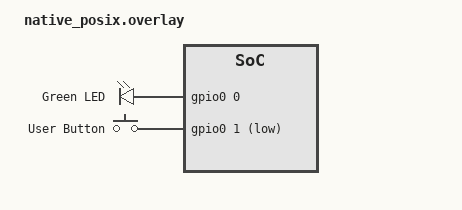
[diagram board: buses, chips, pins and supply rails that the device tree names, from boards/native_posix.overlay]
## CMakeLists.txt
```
# SPDX-License-Identifier: Apache-2.0

cmake_minimum_required(VERSION 3.20.0)

# 1. Tell Zephyr where your out-of-tree module is
set(ZEPHYR_EXTRA_MODULES /home/victor/Documents/Mestrado-UFAL-PPGI/BTreeFy/btreefy-repo)
find_package(Zephyr REQUIRED HINTS $ENV{ZEPHYR_BASE})
project(app LANGUAGES C)

target_sources(app
               PRIVATE
               src/main.c
               src/door_operator_controller.c
               src/btf_nodes_generated.c)

target_link_libraries(app PUBLIC BTreeFy-Src)
```

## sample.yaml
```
sample:
  name: BTreeFy Door Controller
tests:
  example.btreefy.door_controller:
    tags:
      - btreefy
      - behavior-tree
      - gpio
    filter: dt_enabled_alias_with_parent_compat("led0", "gpio-leds") and dt_node_has_alias("sw0")
    depends_on: gpio
    harness: console
    integration_platforms:
      - native_posix
```

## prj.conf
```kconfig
CONFIG_GPIO=y
CONFIG_EVENTS=y
# First config to get POSIX thread running w/o statically allocated stack
CONFIG_POSIX_API=y
CONFIG_THREAD_STACK_INFO=y
CONFIG_DYNAMIC_THREAD=y
CONFIG_DYNAMIC_THREAD_POOL_SIZE=6
CONFIG_MAX_PTHREAD_MUTEX_COUNT=6

# BTreeFy Runner Selection
# CONFIG_BTREEFY_RUNNER_ZEPHYR=y
# Default is POSIX if not set
```

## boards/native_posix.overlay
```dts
/ {
        aliases {
                led0 = &led0;
                sw0 = &button0;
        };

        leds {
                compatible = "gpio-leds";
                led0: led_0 {
                        gpios = <&gpio0 0 GPIO_ACTIVE_HIGH>;
                        label = "Green LED";
                };
        };

        buttons {
                compatible = "gpio-keys";
                button0: button_0 {
                        gpios = <&gpio0 1 (GPIO_PULL_UP | GPIO_ACTIVE_LOW)>;
                        label = "User Button";
                };
        };
};

&gpio0 {
        status = "okay";
        ngpios = <32>;
};
```

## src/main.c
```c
/*
 * Copyright (c) 2016 Intel Corporation
 *
 * SPDX-License-Identifier: Apache-2.0
 */

#include <stdbool.h>
#include <stdio.h>
#include <zephyr/drivers/gpio.h>
#include <zephyr/kernel.h>

#include "app_blackboard.h"
#include "btreefy/btf_blackboard.h"
#include "btreefy/btf_tree_runner.h"
#include "btreefy/btreefy.h"
#include "door_operator_controller.h"

/* 1000 msec = 1 sec */
#define SLEEP_TIME_MS 1000

/* The devicetree node identifier for the "led0" alias. */
#define LED0_NODE DT_ALIAS(led0)

/*
 * Get button configuration from the devicetree sw0 alias. This is mandatory.
 */
#define SW0_NODE DT_ALIAS(sw0)
#if !DT_NODE_HAS_STATUS(SW0_NODE, okay)
#error "Unsupported board: sw0 devicetree alias is not defined"
#endif

extern struct btf_node nodes[];
extern size_t          nodes_size;

/*
 * A build error on this line means your board is unsupported.
 * See the sample documentation for information on how to fix this.
 */
static const struct gpio_dt_spec led = GPIO_DT_SPEC_GET(LED0_NODE, gpios);

static const struct gpio_dt_spec button =
    GPIO_DT_SPEC_GET_OR(SW0_NODE, gpios, {0});
static struct gpio_callback button_cb_data;

static enum btf_node_status mock_open_door_action_status  = BTF_SUCCESS_STATUS;
static enum btf_node_status mock_close_door_action_status = BTF_SUCCESS_STATUS;
static enum btf_node_status mock_stop_door_action_status  = BTF_SUCCESS_STATUS;

static uint8_t button_pressed_count = 0;

static struct k_timer button_timer;
static void           button_timer_cb(struct k_timer *timer_id);

BTF_BLACKBOARD_DEFINE(
    app_blackboard, struct app_blackboard,
    BTF_BLACKBOARD_INIT_VAL(.button_emergency = false, .open_request = false,
                            .close_request          = false,
                            .has_emergency_occurred = false,
                            .door_status            = BTFDT_DOOR_IS_OPEN,
                            .motor_status           = BTFDT_MOTOR_STOP_DOOR));

void button_pressed(const struct device *dev, struct gpio_callback *cb,
                    uint32_t pins)
{
    static int64_t last_button_pressed_evt_time = 0;

    int64_t current_time = k_uptime_get();

    if (current_time - last_button_pressed_evt_time > 50)
    {
        last_button_pressed_evt_time = current_time;
        if (button_pressed_count == 0)
        {
            k_timer_start(&button_timer, K_MSEC(800), K_NO_WAIT);
        }
        button_pressed_count++;
    }
}

void button_timer_cb(struct k_timer *timer_id)
{
    bool is_valid      = true;
    bool flag_occurred = true;

    printf("Button timer callback executed\nbutton_pressed_count = %d\n",
           button_pressed_count);

    switch (button_pressed_count)
    {
    case 1:
    {
        BTF_BLACKBOARD_UPDATE_DATA(app_blackboard, button_emergency,
                                   flag_occurred);
    }
    break;

    case 2:
    {
        BTF_BLACKBOARD_UPDATE_DATA(app_blackboard, open_request, flag_occurred);
        printf("Open request on timer callback\n");
    }
    break;

    case 3:
    {
        BTF_BLACKBOARD_UPDATE_DATA(app_blackboard, close_request,
                                   flag_occurred);
        printf("Close request on timer callback\n");
    }
    break;

    default:
        // Default
        break;
    }

    button_pressed_count = 0;
}

// ### BT ACTIONS - START ###

enum btf_node_status stop_door_action(struct btf_tree *tree, void *data,
                                   size_t datalen)
{
    printf("Door has stopped.\n");
    door_operator_ctrl_set_action(STOP_DOOR);

    return BTF_SUCCESS_STATUS;
}

enum btf_node_status open_door_action(struct btf_tree *tree, void *data,
                                   size_t datalen)
{
    enum btfdt_door_sensor_status door_status;

    printf("Door is opening... ");

    BTF_BLACKBOARD_RETRIEVE_DATA(app_blackboard, door_status, door_status);

    if (door_status != BTFDT_DOOR_IS_OPEN)
    {
        printf(" request ACCEPTED!\n");
        door_operator_ctrl_set_action(OPEN_DOOR);
    }
    else
    {
        printf(" but is alreaedy OPEN, then REJECTED!\n");
    }

    return BTF_SUCCESS_STATUS;
}

enum btf_node_status close_door_action(struct btf_tree *tree, void *data,
                                    size_t datalen)
{
    printf("Door is closing... ");
    door_operator_ctrl_set_action(CLOSE_DOOR);
    return mock_close_door_action_status;
}

enum btf_node_status emergency_action(struct btf_tree *tree, void *data,
                                   size_t datalen)
{
    bool flag_occurred = true;
    printf("Emergency occurred!\n");

    BTF_BLACKBOARD_UPDATE_DATA(app_blackboard, has_emergency_occurred,
                               flag_occurred);

    return BTF_SUCCESS_STATUS;
}

// ### BT ACTIONS - END ###

// ### BT CONDITIONS - START ###

enum btf_node_status is_motor_on_cond(struct btf_tree *tree, void *data,
                                   size_t datalen)
{
    enum btfdt_motor_action_status motor_status;

    BTF_BLACKBOARD_RETRIEVE_DATA(app_blackboard, motor_status, motor_status);

    return (motor_status == BTFDT_MOTOR_STOP_DOOR) ? BTF_FAILURE_STATUS
                                                   : BTF_SUCCESS_STATUS;
}

enum btf_node_status is_emerg_btn_pressed_cond(struct btf_tree *tree, void *data,
                                            size_t datalen)
{
    enum btf_node_status ret = BTF_FAILURE_STATUS;
    bool              flag_occurred;

    BTF_BLACKBOARD_RETRIEVE_DATA(app_blackboard, button_emergency,
                                 flag_occurred);

    if (flag_occurred)
    {
        printf("Emergency button pressed!\n");
        flag_occurred = false;
        BTF_BLACKBOARD_UPDATE_DATA(app_blackboard, button_emergency,
                                   flag_occurred);
        ret = BTF_SUCCESS_STATUS;
    }
    return ret;
}

enum btf_node_status is_open_cond(struct btf_tree *tree, void *data, size_t datalen)
{
    enum btf_node_status             ret = BTF_FAILURE_STATUS;
    enum btfdt_door_sensor_status door_status;

    BTF_BLACKBOARD_RETRIEVE_DATA(app_blackboard, door_status, door_status);

    if (door_status == BTFDT_DOOR_IS_OPEN)
    {
        ret = BTF_SUCCESS_STATUS;
        printf("Door is open\n");
    }
    else if (door_status == BTFDT_DOOR_IS_CLOSED)
    {
        printf("Door is closed\n");
    }

    return ret;
}

enum btf_node_status is_opening_cond(struct btf_tree *tree, void *data, size_t datalen)
{
    enum btf_node_status              ret = BTF_FAILURE_STATUS;
    enum btfdt_door_sensor_status  door_status;
    enum btfdt_motor_action_status motor_status;

    BTF_BLACKBOARD_RETRIEVE_DATA(app_blackboard, door_status, door_status);
    BTF_BLACKBOARD_RETRIEVE_DATA(app_blackboard, motor_status, motor_status);

    if ((door_status == BTFDT_DOOR_IS_UNDEFINED)
        && (motor_status == BTFDT_MOTOR_OPEN_DOOR))
    {
        ret = BTF_SUCCESS_STATUS;
    }

    return ret;
}

enum btf_node_status is_closed_cond(struct btf_tree *tree, void *data, size_t datalen)
{
    enum btf_node_status             ret = BTF_FAILURE_STATUS;
    enum btfdt_door_sensor_status door_status;

    BTF_BLACKBOARD_RETRIEVE_DATA(app_blackboard, door_status, door_status);

    if (door_status == BTFDT_DOOR_IS_CLOSED)
    {
        ret = BTF_SUCCESS_STATUS;
        printf("Door is closed\n");
    }
    else if (door_status == BTFDT_DOOR_IS_OPEN)
    {
        printf("Door is open\n");
    }

    return ret;
}

enum btf_node_status is_closing_cond(struct btf_tree *tree, void *data, size_t datalen)
{
    enum btf_node_status              ret = BTF_FAILURE_STATUS;
    enum btfdt_door_sensor_status  door_status;
    enum btfdt_motor_action_status motor_status;

    BTF_BLACKBOARD_RETRIEVE_DATA(app_blackboard, door_status, door_status);
    BTF_BLACKBOARD_RETRIEVE_DATA(app_blackboard, motor_status, motor_status);

    if ((door_status == BTFDT_DOOR_IS_UNDEFINED)
        && (motor_status == BTFDT_MOTOR_CLOSE_DOOR))
    {
        ret = BTF_SUCCESS_STATUS;
    }

    return ret;
}

enum btf_node_status has_emergency_ocurred_cond(struct btf_tree *tree, void *data,
                                             size_t datalen)
{
    enum btf_node_status ret = BTF_FAILURE_STATUS;
    bool              flag_occurred;

    BTF_BLACKBOARD_RETRIEVE_DATA(app_blackboard, has_emergency_occurred,
                                 flag_occurred);

    if (flag_occurred)
    {
        flag_occurred = false;
        BTF_BLACKBOARD_UPDATE_DATA(app_blackboard, has_emergency_occurred,
                                   flag_occurred);
        ret = BTF_SUCCESS_STATUS;
    }

    return ret;
}

enum btf_node_status open_door_request_cond(struct btf_tree *tree, void *data,
                                         size_t datalen)
{
    enum btf_node_status ret = BTF_FAILURE_STATUS;
    bool              flag_occurred;

    BTF_BLACKBOARD_RETRIEVE_DATA(app_blackboard, open_request, flag_occurred);

    if (flag_occurred)
    {
        printf("Open door request!\n");
        flag_occurred = false;
        BTF_BLACKBOARD_UPDATE_DATA(app_blackboard, open_request, flag_occurred);
        ret = BTF_SUCCESS_STATUS;
    }

    return ret;
}

enum btf_node_status close_door_request_cond(struct btf_tree *tree, void *data,
                                          size_t datalen)
{
    enum btf_node_status ret = BTF_FAILURE_STATUS;
    bool              flag_occurred;

    BTF_BLACKBOARD_RETRIEVE_DATA(app_blackboard, close_request, flag_occurred);

    if (flag_occurred)
    {
        printf("Close door request!\n");
        flag_occurred = false;
        BTF_BLACKBOARD_UPDATE_DATA(app_blackboard, close_request,
                                   flag_occurred);
        ret = BTF_SUCCESS_STATUS;
    }

    return ret;
}

// ### BT CONDITIONS - END ###


int main(void)
{
    int  ret;
    bool led_state = true;

    struct btf_tree tree;
    int32_t     status;

    if (!gpio_is_ready_dt(&led))
    {
        return 0;
    }

    ret = gpio_pin_configure_dt(&led, GPIO_OUTPUT_ACTIVE);
    if (ret < 0)
    {
        return 0;
    }

    if (!gpio_is_ready_dt(&button))
    {
        printk("Error: button device %s is not ready\n", button.port->name);
        return 0;
    }

    k_timer_init(&button_timer, button_timer_cb, NULL);

    ret = gpio_pin_configure_dt(&button, GPIO_INPUT);
    if (ret != 0)
    {
        printk("Error %d: failed to configure %s pin %d\n", ret,
               button.port->name, button.pin);
        return 0;
    }

    ret = gpio_pin_interrupt_configure_dt(&button, GPIO_INT_EDGE_TO_ACTIVE);
    if (ret != 0)
    {
        printk("Error %d: failed to configure interrupt on %s pin %d\n", ret,
               button.port->name, button.pin);
        return 0;
    }

    gpio_init_callback(&button_cb_data, button_pressed, BIT(button.pin));
    gpio_add_callback(button.port, &button_cb_data);
    printk("Set up button at %s pin %d\n", button.port->name, button.pin);

    if (door_operator_ctrl_init())
    {
        return 0;
    }

    if (btf_init(&tree, nodes, nodes_size) == 0)
    {
    }

    if (btf_runner_init(&tree))
    {
    }

    while (1)
    {
        k_msleep(1000);
    }

    return 0;
}
```

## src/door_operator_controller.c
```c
/**
 * @file door_operator_controller.c
 * @author Victor Oliveira (victor.rsoliveira@gmail.com)
 * @brief
 * @version 0.1
 * @date 2025-06-17
 *
 */

#include "door_operator_controller.h"

#include <zephyr/kernel.h>

#include "btreefy/btf_tree_runner.h"
#include "btreefy/btf_blackboard.h"
#include "app_blackboard.h"

static char *door_sensor_status_string[] = {[DOOR_IS_UNDEFINED] = "UNDEFINED",
                                            [DOOR_IS_OPEN]      = "OPEN",
                                            [DOOR_IS_CLOSED]    = "CLOSED"};


struct k_timer door_sensor_timer;
static void    door_sensor_timer_cb(struct k_timer *timer_id);

BTF_BLACKBOARD_DECLARE(app_blackboard, struct app_blackboard);


int door_operator_ctrl_init(void)
{
    k_timer_init(&door_sensor_timer, door_sensor_timer_cb, NULL);
    return 0;
}

char *door_operator_ctrl_get_sensor_status_string(
    enum door_sensor_status status)
{
    return door_sensor_status_string[status];
}

int door_operator_ctrl_set_action(enum door_action action)
{
    enum btfdt_door_sensor_status door_status;
    enum btfdt_motor_action_status motor_status;

    BTF_BLACKBOARD_RETRIEVE_DATA(app_blackboard,  motor_status, motor_status);

    if ((enum btfdt_motor_action_status) action != motor_status)
    {
        BTF_BLACKBOARD_UPDATE_DATA(app_blackboard,  motor_status, action);

        if ((action == OPEN_DOOR) || (action == CLOSE_DOOR))
        {
            door_status = BTFDT_DOOR_IS_UNDEFINED;
            BTF_BLACKBOARD_UPDATE_DATA(app_blackboard,  door_status, door_status);
            k_timer_start(&door_sensor_timer, K_MSEC(4000), K_NO_WAIT);
        }
        else
        {
            k_timer_stop(&door_sensor_timer);
        }
    }

    return 0;
}

static void door_sensor_timer_cb(struct k_timer *timer_id)
{
    enum btfdt_door_sensor_status door_status;
    enum btfdt_motor_action_status motor_status;

    printf("Door sensor timer callback\n");

    BTF_BLACKBOARD_RETRIEVE_DATA(app_blackboard,  motor_status, motor_status);
    if (motor_status == BTFDT_MOTOR_OPEN_DOOR)
    {
        door_status = BTFDT_DOOR_IS_OPEN;
        BTF_BLACKBOARD_UPDATE_DATA(app_blackboard,  door_status, door_status);
    }
    else if (motor_status == BTFDT_MOTOR_CLOSE_DOOR)
    {
        door_status = BTFDT_DOOR_IS_CLOSED;
        BTF_BLACKBOARD_UPDATE_DATA(app_blackboard,  door_status, door_status);
    }
    else
    {
        // NEVER OCCURS
    }
}
```

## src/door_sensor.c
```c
/**
 * @file door_sensor.c
 * @author Victor Oliveira (victor.rsoliveira@gmail.com)
 * @brief
 * @version 0.1
 * @date 2025-06-15
 *
 */

#include "door_sensor.h"

#include <zephyr/kernel.h>

#define DOOR_SENSOR_STATUS_INITIAL_VALUE DOOR_IS_CLOSED

static char *door_sensor_status_string[] = {
    [DOOR_IS_OPEN]    = "OPEN",
    [DOOR_IS_CLOSED]  = "CLOSED",
    [DOOR_IS_OPENING] = "OPENING",
    [DOOR_IS_CLOSING] = "CLOSING",
};


static enum door_sensor_status door_sensor_status =
    DOOR_SENSOR_STATUS_INITIAL_VALUE;

struct k_timer door_sensor_timer;
void           door_sensor_timer_cb(struct k_timer *timer_id);

int bt_app_door_sensor_init(void)
{
    door_sensor_status = DOOR_SENSOR_STATUS_INITIAL_VALUE;

    k_timer_init(&door_sensor_timer, door_sensor_timer_cb, NULL);

    return 0;
}

enum door_sensor_status bt_app_door_sensor_get_status(void)
{
    return door_sensor_status;
}

char * bt_app_door_sensor_get_status_string(enum door_sensor_status status)
{
    return door_sensor_status_string[status];
}

int bt_app_door_sensor_set_status(enum door_sensor_status status)
{
    switch (door_sensor_status)
    {
    case DOOR_IS_OPEN:
    {
        if (status == DOOR_IS_CLOSING)
        {
            door_sensor_status = status;
            k_timer_start(&door_sensor_timer, K_MSEC(1500), K_NO_WAIT);
        }
    }
    break;

    case DOOR_IS_CLOSED:
    {
        if (status == DOOR_IS_OPENING)
        {
            door_sensor_status = status;
            k_timer_start(&door_sensor_timer, K_MSEC(1500), K_NO_WAIT);
        }
    }
    break;

    case DOOR_IS_OPENING:
    {
    }
    break;

    case DOOR_IS_CLOSING:
    {
    }
    break;

    default:
    {
    }
    break;
    }

    return 0;
}

void door_sensor_timer_cb(struct k_timer *timer_id)
{
    switch (door_sensor_status)
    {
    case DOOR_IS_CLOSING:
    {
        door_sensor_status = DOOR_IS_CLOSED;
        printf("Door is closed.\n");
    }
    break;

    case DOOR_IS_OPENING:
    {
        door_sensor_status = DOOR_IS_OPEN;
        printf("Door is open.\n");
    }
    break;

    default:
        /* code */
        break;
    }
}
```
